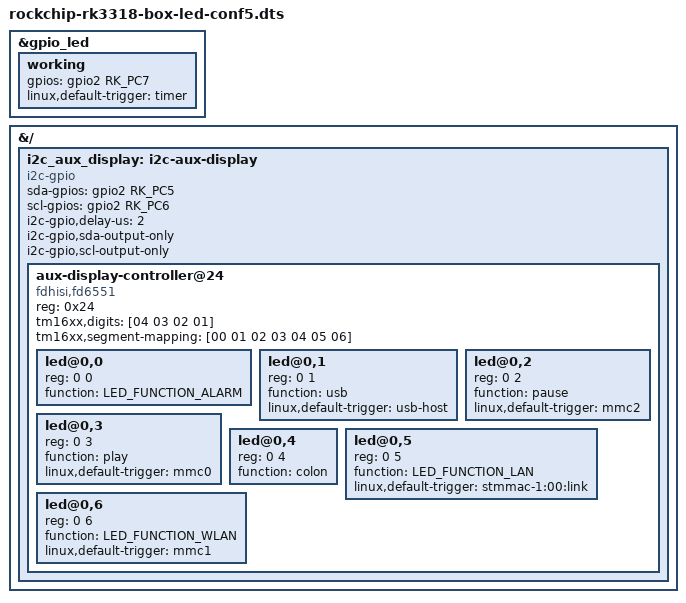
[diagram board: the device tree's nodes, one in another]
/dts-v1/;
/plugin/;

#include <dt-bindings/gpio/gpio.h>
#include <dt-bindings/input/input.h>
#include <dt-bindings/pinctrl/rockchip.h>
#include <dt-bindings/leds/common.h>

/**
 * YX_RK3318 (circular) board
 */

&gpio_led {

	working {
		gpios = <&gpio2 RK_PC7 GPIO_ACTIVE_HIGH>;
		linux,default-trigger = "timer";
	};

};

&{/} {

	i2c_aux_display: i2c-aux-display {

		compatible = "i2c-gpio";
		sda-gpios = <&gpio2 RK_PC5 (GPIO_ACTIVE_HIGH|GPIO_OPEN_DRAIN)>;
		scl-gpios = <&gpio2 RK_PC6 (GPIO_ACTIVE_HIGH|GPIO_OPEN_DRAIN)>;
		i2c-gpio,delay-us = <2>;
		i2c-gpio,sda-output-only;
		i2c-gpio,scl-output-only;
		#address-cells = <1>;
		#size-cells = <0>;

		aux-display-controller@24 {
			compatible = "fdhisi,fd6551";
			reg = <0x24>;

			tm16xx,digits = [04 03 02 01];
			tm16xx,segment-mapping = [00 01 02 03 04 05 06];

			#address-cells = <2>;
			#size-cells = <0>;

			led@0,0 {
				reg = <0 0>;
				function = LED_FUNCTION_ALARM;
			};

			led@0,1 {
				reg = <0 1>;
				function = "usb";
				linux,default-trigger = "usb-host";
			};

			led@0,2 {
				reg = <0 2>;
				function = "pause";
				linux,default-trigger = "mmc2";
			};

			led@0,3 {
				reg = <0 3>;
				function = "play";
				linux,default-trigger = "mmc0";
			};

			led@0,4 {
				reg = <0 4>;
				function = "colon";
			};

			led@0,5 {
				reg = <0 5>;
				function = LED_FUNCTION_LAN;
				linux,default-trigger = "stmmac-1:00:link";
			};

			led@0,6 {
				reg = <0 6>;
				function = LED_FUNCTION_WLAN;
				linux,default-trigger = "mmc1";
			};

		};
	};

};

/*
 * TODO: needs to find the GPIO for this
 *
&gpio_keys {

	reset {
		gpios = <&gpio3 RK_PD1 GPIO_ACTIVE_LOW>;
		label = "reset";
		linux,code = <KEY_RESTART>;
		debounce-interval = <200>;
		wakeup-source;
	};

};
*/
